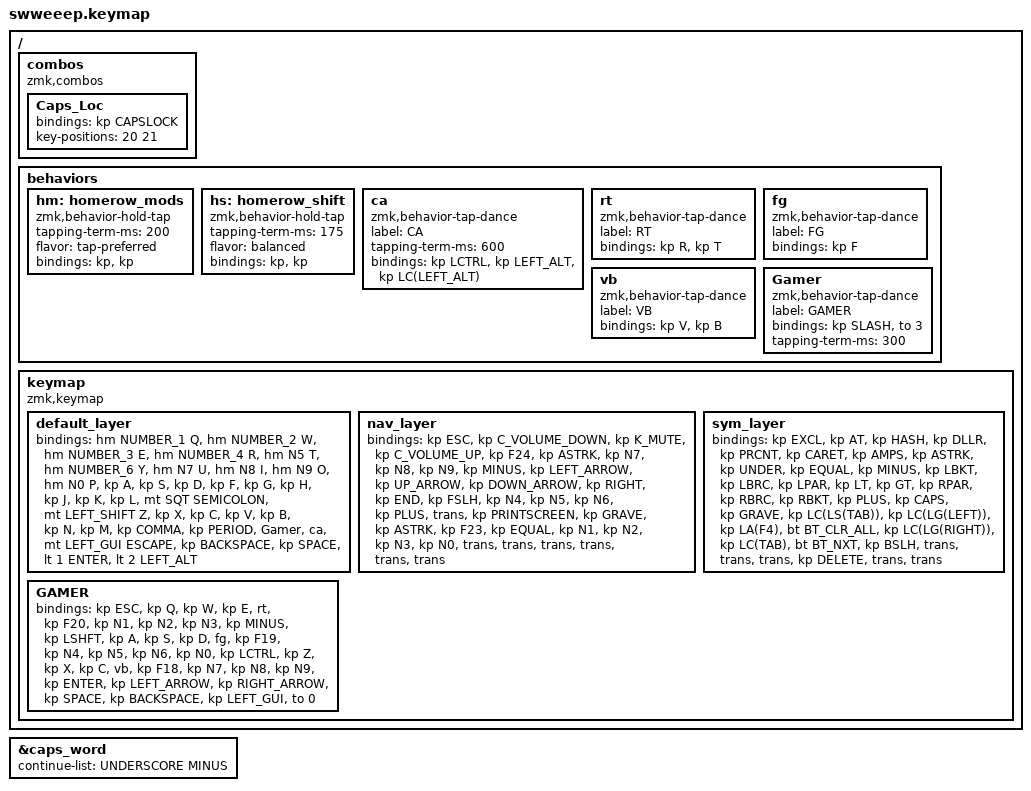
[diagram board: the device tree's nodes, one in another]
#include <behaviors.dtsi>
#include <dt-bindings/zmk/bt.h>
#include <dt-bindings/zmk/keys.h>

#define DEFAULT 0
#define NAV     1
#define SYM     2
#define GAM     3

&caps_word { continue-list = <UNDERSCORE MINUS>; };

/ {
    combos {
        compatible = "zmk,combos";

        Caps_Loc {
            bindings = <&kp CAPSLOCK>;
            key-positions = <20 21>;
        };
    };
};

/ {
    behaviors {
        hm: homerow_mods {
            compatible = "zmk,behavior-hold-tap";
            #binding-cells = <2>;
            tapping-term-ms = <200>;
            flavor = "tap-preferred";
            bindings = <&kp>, <&kp>;
        };

        hs: homerow_shift {
            compatible = "zmk,behavior-hold-tap";
            #binding-cells = <2>;
            tapping-term-ms = <175>;
            flavor = "balanced";
            bindings = <&kp>, <&kp>;
        };

        ca: ca {
            compatible = "zmk,behavior-tap-dance";
            label = "CA";
            #binding-cells = <0>;
            tapping-term-ms = <600>;
            bindings = <&kp LCTRL>, <&kp LEFT_ALT>, <&kp LC(LEFT_ALT)>;
        };

        rt: rt {
            compatible = "zmk,behavior-tap-dance";
            label = "RT";
            #binding-cells = <0>;
            bindings = <&kp R>, <&kp T>;
        };

        fg: fg {
            compatible = "zmk,behavior-tap-dance";
            label = "FG";
            #binding-cells = <0>;
            bindings = <&kp F>;
        };

        vb: vb {
            compatible = "zmk,behavior-tap-dance";
            label = "VB";
            #binding-cells = <0>;
            bindings = <&kp V>, <&kp B>;
        };

        Gamer: Gamer {
            compatible = "zmk,behavior-tap-dance";
            label = "GAMER";
            #binding-cells = <0>;
            bindings = <&kp SLASH>, <&to 3>;

            tapping-term-ms = <300>;
        };
    };

    keymap {
        compatible = "zmk,keymap";

        default_layer {
            bindings = <
&hm NUMBER_1 Q  &hm NUMBER_2 W  &hm NUMBER_3 E  &hm NUMBER_4 R  &hm N5 T  &hm NUMBER_6 Y  &hm N7 U  &hm N8 I  &hm N9 O  &hm N0 P  &kp A  &kp S  &kp D  &kp F  &kp G  &kp H  &kp J  &kp K  &kp L  &mt SQT SEMICOLON  &mt LEFT_SHIFT Z  &kp X  &kp C  &kp V  &kp B  &kp N  &kp M  &kp COMMA  &kp PERIOD  &Gamer  &ca  &mt LEFT_GUI ESCAPE  &kp BACKSPACE  &kp SPACE  &lt 1 ENTER  &lt 2 LEFT_ALT
            >;
        };

        nav_layer {
            bindings = <
&kp ESC  &kp C_VOLUME_DOWN  &kp K_MUTE  &kp C_VOLUME_UP  &kp F24  &kp ASTRK  &kp N7  &kp N8  &kp N9  &kp MINUS  &kp LEFT_ARROW  &kp UP_ARROW  &kp DOWN_ARROW  &kp RIGHT  &kp END  &kp FSLH  &kp N4  &kp N5  &kp N6  &kp PLUS  &trans  &kp PRINTSCREEN  &kp GRAVE  &kp ASTRK  &kp F23  &kp EQUAL  &kp N1  &kp N2  &kp N3  &kp N0  &trans  &trans  &trans  &trans  &trans  &trans
            >;
        };

        sym_layer {
            bindings = <
&kp EXCL  &kp AT  &kp HASH  &kp DLLR  &kp PRCNT  &kp CARET  &kp AMPS  &kp ASTRK  &kp UNDER  &kp EQUAL  &kp MINUS  &kp LBKT  &kp LBRC  &kp LPAR  &kp LT  &kp GT  &kp RPAR  &kp RBRC  &kp RBKT  &kp PLUS  &kp CAPS  &kp GRAVE  &kp LC(LS(TAB))  &kp LC(LG(LEFT))  &kp LA(F4)  &bt BT_CLR_ALL  &kp LC(LG(RIGHT))  &kp LC(TAB)  &bt BT_NXT  &kp BSLH  &trans  &trans  &trans  &kp DELETE  &trans  &trans
            >;
        };

        GAMER {
            bindings = <
&kp ESC  &kp Q  &kp W  &kp E  &rt  &kp F20  &kp N1  &kp N2  &kp N3  &kp MINUS  &kp LSHFT  &kp A  &kp S  &kp D  &fg  &kp F19  &kp N4  &kp N5  &kp N6  &kp N0  &kp LCTRL  &kp Z  &kp X  &kp C  &vb  &kp F18  &kp N7  &kp N8  &kp N9  &kp ENTER  &kp LEFT_ARROW  &kp RIGHT_ARROW  &kp SPACE  &kp BACKSPACE  &kp LEFT_GUI  &to 0
            >;
        };
    };
};
